# MAIN_CTRL_MMR_MAIN_CTRL_MMR_CFG0_00100000h register map
Vendor: Texas Instruments
Registers are 32-bit, read-write, reset 0x0 unless marked. A register's access mark holds for its fields unless they carry their own. Offsets are as the file gives them; [hi:lo] are bit positions; {n}, {i} and the like mark numbered series.

## main_ctrl_mmr_CFG0 (part 2 of 3)
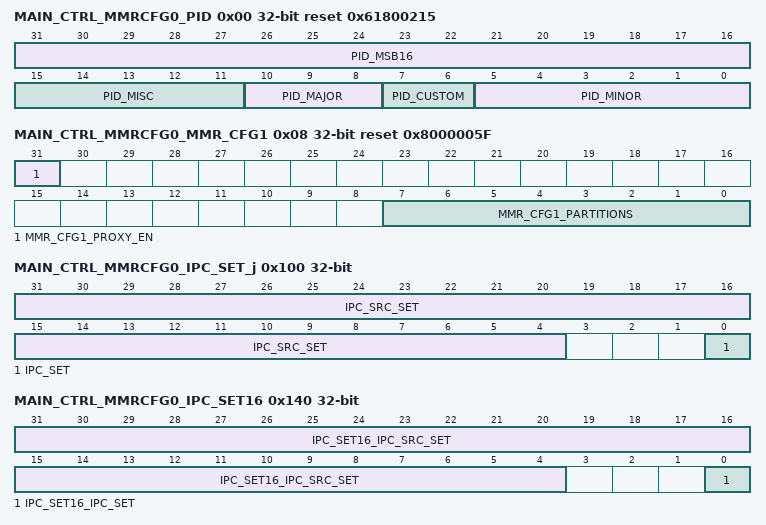
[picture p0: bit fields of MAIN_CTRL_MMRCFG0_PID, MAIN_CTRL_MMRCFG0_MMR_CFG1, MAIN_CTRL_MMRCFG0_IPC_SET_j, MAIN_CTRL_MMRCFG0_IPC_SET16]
0x00 MAIN_CTRL_MMRCFG0_PID ro reset 0x61800215
  [31:16] PID_MSB16 — Reset Source: mod_g_rst_n
  [15:11] PID_MISC — Reset Source: mod_g_rst_n
  [10:8] PID_MAJOR — Reset Source: mod_g_rst_n
  [7:6] PID_CUSTOM — Reset Source: mod_g_rst_n
  [5:0] PID_MINOR — Reset Source: mod_g_rst_n
0x08 MAIN_CTRL_MMRCFG0_MMR_CFG1 ro reset 0x8000005F — Indicates the MMR configuration
  [31] MMR_CFG1_PROXY_EN — Proxy addressing enabled Reset Source: mod_por_rst_n
  [7:0] MMR_CFG1_PARTITIONS — Indicates present partitions Reset Source: mod_por_rst_n
0x100 MAIN_CTRL_MMRCFG0_IPC_SET_j access not given — Generate interprocessor communication interrupt to C71x core0
  [31:4] IPC_SRC_SET — Read returns current valueWrite: 0 - No effect 1 - Sets both corresponding IPC_CLR and the IPC_SET bits Reset Source: mod_g_rst_n (access R/W1TS)
  [0] IPC_SET — Read returns 0Write: 0 - No effect 1 - Sets both corresponding IPC_CLR and the IPC_SET bits Reset Source: mod_g_rst_n (access R/W1TS)
0x140 MAIN_CTRL_MMRCFG0_IPC_SET16 access not given — Generate interprocessor communication interrupt to MAIN R5 cluster0 core0
  [31:4] IPC_SET16_IPC_SRC_SET — Read returns current valueWrite: 0 - No effect 1 - Sets both corresponding IPC_CLR and the IPC_SET bits Reset Source: mod_g_rst_n (access R/W1TS)
  [0] IPC_SET16_IPC_SET — Read returns 0Write: 0 - No effect 1 - Sets both corresponding IPC_CLR and the IPC_SET bits Reset Source: mod_g_rst_n (access R/W1TS)
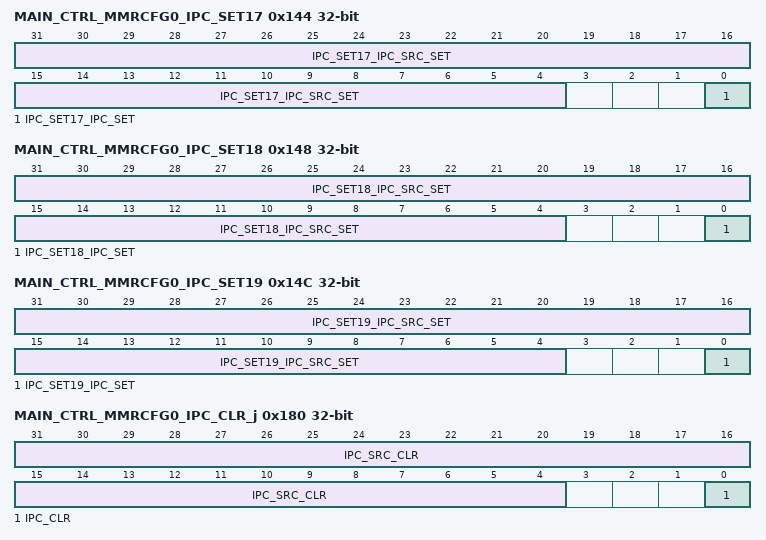
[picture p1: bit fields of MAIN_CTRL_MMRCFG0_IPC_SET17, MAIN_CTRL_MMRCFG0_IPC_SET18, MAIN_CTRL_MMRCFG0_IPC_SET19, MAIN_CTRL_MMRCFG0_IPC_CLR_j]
0x144 MAIN_CTRL_MMRCFG0_IPC_SET17 access not given — Generate interprocessor communication interrupt to MAIN R5 cluster0 core1
  [31:4] IPC_SET17_IPC_SRC_SET — Read returns current valueWrite: 0 - No effect 1 - Sets both corresponding IPC_CLR and the IPC_SET bits Reset Source: mod_g_rst_n (access R/W1TS)
  [0] IPC_SET17_IPC_SET — Read returns 0Write: 0 - No effect 1 - Sets both corresponding IPC_CLR and the IPC_SET bits Reset Source: mod_g_rst_n (access R/W1TS)
0x148 MAIN_CTRL_MMRCFG0_IPC_SET18 access not given — Generate interprocessor communication interrupt to MAIN R5 cluster1 core0
  [31:4] IPC_SET18_IPC_SRC_SET — Read returns current valueWrite: 0 - No effect 1 - Sets both corresponding IPC_CLR and the IPC_SET bits Reset Source: mod_g_rst_n (access R/W1TS)
  [0] IPC_SET18_IPC_SET — Read returns 0Write: 0 - No effect 1 - Sets both corresponding IPC_CLR and the IPC_SET bits Reset Source: mod_g_rst_n (access R/W1TS)
0x14C MAIN_CTRL_MMRCFG0_IPC_SET19 access not given — Generate interprocessor communication interrupt to MAIN R5 cluster1 core1
  [31:4] IPC_SET19_IPC_SRC_SET — Read returns current valueWrite: 0 - No effect 1 - Sets both corresponding IPC_CLR and the IPC_SET bits Reset Source: mod_g_rst_n (access R/W1TS)
  [0] IPC_SET19_IPC_SET — Read returns 0Write: 0 - No effect 1 - Sets both corresponding IPC_CLR and the IPC_SET bits Reset Source: mod_g_rst_n (access R/W1TS)
0x180 MAIN_CTRL_MMRCFG0_IPC_CLR_j access not given — Acknowledge interprocessor communication interrupt to C71x core0
  [31:4] IPC_SRC_CLR — Read returns current valueWrite: 0 - No effect 1 - Clears both corresponding IPC_CLR and the IPC_SET bits Reset Source: mod_g_rst_n (access R/W1TC)
  [0] IPC_CLR — Read returns current valueWrite: 0 - No effect 1 - Clears both corresponding IPC_CLR and the IPC_SET bits Reset Source: mod_g_rst_n (access R/W1TC)
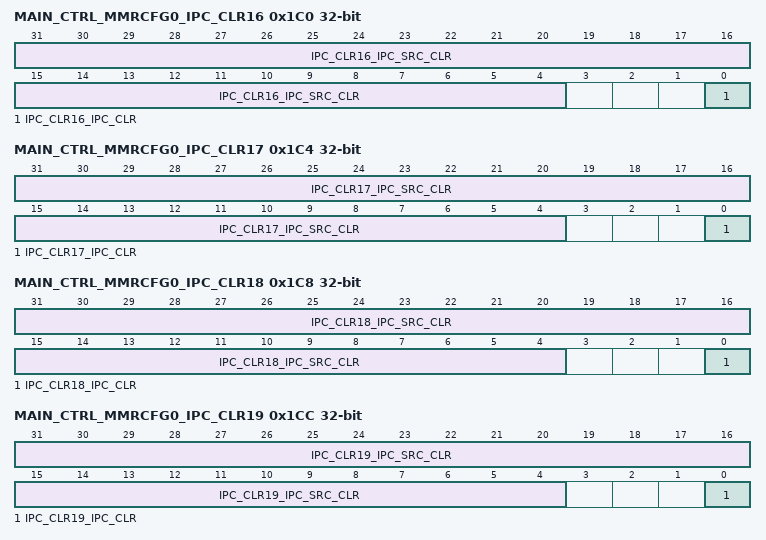
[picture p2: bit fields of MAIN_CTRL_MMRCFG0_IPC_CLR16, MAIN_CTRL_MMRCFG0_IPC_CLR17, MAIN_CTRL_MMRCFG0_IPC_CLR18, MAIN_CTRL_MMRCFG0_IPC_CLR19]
0x1C0 MAIN_CTRL_MMRCFG0_IPC_CLR16 access not given — Acknowledge interprocessor communication interrupt to MAIN R5 cluster0 core0
  [31:4] IPC_CLR16_IPC_SRC_CLR — Read returns current valueWrite: 0 - No effect 1 - Clears both corresponding IPC_CLR and the IPC_SET bits Reset Source: mod_g_rst_n (access R/W1TC)
  [0] IPC_CLR16_IPC_CLR — Read returns current valueWrite: 0 - No effect 1 - Clears both corresponding IPC_CLR and the IPC_SET bits Reset Source: mod_g_rst_n (access R/W1TC)
0x1C4 MAIN_CTRL_MMRCFG0_IPC_CLR17 access not given — Acknowledge interprocessor communication interrupt to MAIN R5 cluster0 core1
  [31:4] IPC_CLR17_IPC_SRC_CLR — Read returns current valueWrite: 0 - No effect 1 - Clears both corresponding IPC_CLR and the IPC_SET bits Reset Source: mod_g_rst_n (access R/W1TC)
  [0] IPC_CLR17_IPC_CLR — Read returns current valueWrite: 0 - No effect 1 - Clears both corresponding IPC_CLR and the IPC_SET bits Reset Source: mod_g_rst_n (access R/W1TC)
0x1C8 MAIN_CTRL_MMRCFG0_IPC_CLR18 access not given — Acknowledge interprocessor communication interrupt to MAIN R5 cluster1 core2
  [31:4] IPC_CLR18_IPC_SRC_CLR — Read returns current valueWrite: 0 - No effect 1 - Clears both corresponding IPC_CLR and the IPC_SET bits Reset Source: mod_g_rst_n (access R/W1TC)
  [0] IPC_CLR18_IPC_CLR — Read returns current valueWrite: 0 - No effect 1 - Clears both corresponding IPC_CLR and the IPC_SET bits Reset Source: mod_g_rst_n (access R/W1TC)
0x1CC MAIN_CTRL_MMRCFG0_IPC_CLR19 access not given — Acknowledge interprocessor communication interrupt to MAIN R5 cluster1 core3
  [31:4] IPC_CLR19_IPC_SRC_CLR — Read returns current valueWrite: 0 - No effect 1 - Clears both corresponding IPC_CLR and the IPC_SET bits Reset Source: mod_g_rst_n (access R/W1TC)
  [0] IPC_CLR19_IPC_CLR — Read returns current valueWrite: 0 - No effect 1 - Clears both corresponding IPC_CLR and the IPC_SET bits Reset Source: mod_g_rst_n (access R/W1TC)
{0x1008+0x4000*i} MAIN_CTRL_MMRCFG0_LOCK{i}_KICK0 (i=0..3)
  [31:0] LOCK{i}_KICK0 — - KICK0 component Reset Source: mod_g_rst_n
{0x100C+0x4000*i} MAIN_CTRL_MMRCFG0_LOCK{i}_KICK1 (i=0..3)
  [31:0] LOCK{i}_KICK1 — - KICK1 component Reset Source: mod_g_rst_n
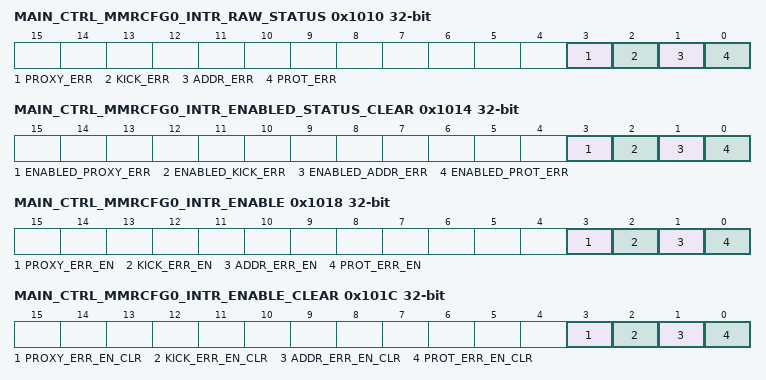
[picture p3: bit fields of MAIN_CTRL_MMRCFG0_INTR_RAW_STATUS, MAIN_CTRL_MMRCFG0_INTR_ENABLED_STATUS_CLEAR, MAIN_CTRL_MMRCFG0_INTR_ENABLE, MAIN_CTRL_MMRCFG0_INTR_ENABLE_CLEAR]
0x1010 MAIN_CTRL_MMRCFG0_INTR_RAW_STATUS access not given
  [3] PROXY_ERR — Proxy0 access violation error. Raw status is read. Write a 1 to set the status. Writing a 0 has no effect. Reset Source: mod_g_rst_n (access R/W1TS)
  [2] KICK_ERR — Kick access violation error. Raw status is read. Write a 1 to set the status. Writing a 0 has no effect. Reset Source: mod_g_rst_n (access R/W1TS)
  [1] ADDR_ERR — Addressing violation error. Raw status is read. Write a 1 to set the status. Writing a 0 has no effect. Reset Source: mod_g_rst_n (access R/W1TS)
  [0] PROT_ERR — Protection violation error. Raw status is read. Write a 1 to set the status. Writing a 0 has no effect. Reset Source: mod_g_rst_n (access R/W1TS)
0x1014 MAIN_CTRL_MMRCFG0_INTR_ENABLED_STATUS_CLEAR access not given
  [3] ENABLED_PROXY_ERR — Proxy0 access violation error. Enabled status is read. Write a 1 to clear the status. Writing a 0 has no effect. Reset Source: mod_g_rst_n (access R/W1TC)
  [2] ENABLED_KICK_ERR — Kick access violation error. Enabled status is read. Write a 1 to clear the status. Writing a 0 has no effect. Reset Source: mod_g_rst_n (access R/W1TC)
  [1] ENABLED_ADDR_ERR — Addressing violation error. Enabled status is read. Write a 1 to clear the status. Writing a 0 has no effect. Reset Source: mod_g_rst_n (access R/W1TC)
  [0] ENABLED_PROT_ERR — Protection violation error. Enabled status is read. Write a 1 to clear the status. Writing a 0 has no effect. Reset Source: mod_g_rst_n (access R/W1TC)
0x1018 MAIN_CTRL_MMRCFG0_INTR_ENABLE access not given
  [3] PROXY_ERR_EN — Proxy0 access violation error enable. Write a 1 to set the enable. Writing a 0 has no effect. Reset Source: mod_g_rst_n (access R/W1TS)
  [2] KICK_ERR_EN — Kick access violation error enable. Write a 1 to set the enable. Writing a 0 has no effect. Reset Source: mod_g_rst_n (access R/W1TS)
  [1] ADDR_ERR_EN — Addressing violation error enable. Write a 1 to set the enable. Writing a 0 has no effect. Reset Source: mod_g_rst_n (access R/W1TS)
  [0] PROT_ERR_EN — Protection violation error enable. Write a 1 to set the enable. Writing a 0 has no effect. Reset Source: mod_g_rst_n (access R/W1TS)
0x101C MAIN_CTRL_MMRCFG0_INTR_ENABLE_CLEAR access not given
  [3] PROXY_ERR_EN_CLR — Proxy0 access violation error enable clear. Write a 1 to clear the enable. Writing a 0 has no effect. Reset Source: mod_g_rst_n (access R/W1TC)
  [2] KICK_ERR_EN_CLR — Kick access violation error enable clear. Write a 1 to clear the enable. Writing a 0 has no effect. Reset Source: mod_g_rst_n (access R/W1TC)
  [1] ADDR_ERR_EN_CLR — Addressing violation error enable clear. Write a 1 to clear the enable. Writing a 0 has no effect. Reset Source: mod_g_rst_n (access R/W1TC)
  [0] PROT_ERR_EN_CLR — Protection violation error enable clear. Write a 1 to clear the enable. Writing a 0 has no effect. Reset Source: mod_g_rst_n (access R/W1TC)
0x1020 MAIN_CTRL_MMRCFG0_EOI
  [7:0] EOI_VECTOR — EOI vector value. Write this with interrupt distribution value in the chip. Reset Source: mod_g_rst_n
0x1024 MAIN_CTRL_MMRCFG0_FAULT_ADDRESS ro
  [31:0] FAULT_ADDR — Fault Address. Reset Source: mod_g_rst_n
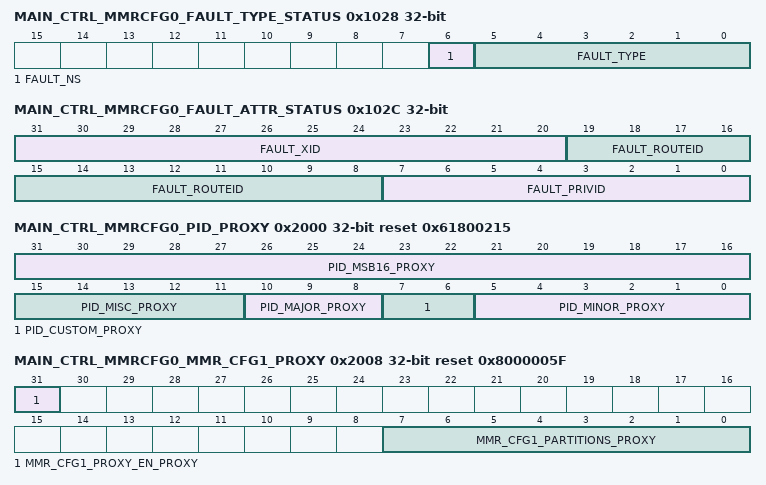
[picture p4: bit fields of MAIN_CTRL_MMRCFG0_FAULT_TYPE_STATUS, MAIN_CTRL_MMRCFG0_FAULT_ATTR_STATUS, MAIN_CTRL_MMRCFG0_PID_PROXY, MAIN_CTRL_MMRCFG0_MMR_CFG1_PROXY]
0x1028 MAIN_CTRL_MMRCFG0_FAULT_TYPE_STATUS ro
  [6] FAULT_NS — Non-secure access. Reset Source: mod_g_rst_n
  [5:0] FAULT_TYPE — Fault Type 10_0000 = Supervisor read fault - priv = 1 dir = 1 dtype != 1 01_0000 = Supervisor write fault - priv = 1 dir = 0 00_1000 = Supervisor execute fault - priv = 1 dir = 1 dtype = 1 00_0100 = User read fault - priv = 0 dir = 1 dtype = 1 00_0010 = User write fault - priv = 0 dir = 0 00_0001 = User execute fault - priv = 0 dir = 1 dtype = 1 00_0000 = No fault Reset Source: mod_g_rst_n
0x102C MAIN_CTRL_MMRCFG0_FAULT_ATTR_STATUS ro
  [31:20] FAULT_XID — XID. Reset Source: mod_g_rst_n
  [19:8] FAULT_ROUTEID — Route ID. Reset Source: mod_g_rst_n
  [7:0] FAULT_PRIVID — Privilege ID. Reset Source: mod_g_rst_n
0x1030 MAIN_CTRL_MMRCFG0_FAULT_CLEAR wo
  [0] FAULT_CLR — Fault clear. Writing a 1 clears the current fault. Writing a 0 has no effect. Reset Source: mod_g_rst_n
{0x1100+0x4000*i} MAIN_CTRL_MMRCFG0_CLAIMREG_P{i}_R0_READONLY ro (i=0..3)
  [31:0] CLAIMREG_P{i}_R0_READONLY — Claim bits for Partition {i} Reset Source: mod_g_rst_n
{0x1108+0x4000*i} MAIN_CTRL_MMRCFG0_CLAIMREG_P{i}_R2_READONLY ro (i=0..2)
  [31:0] CLAIMREG_P{i}_R2_READONLY — Claim bits for Partition {i} Reset Source: mod_g_rst_n
{0x110C+0x4000*i} MAIN_CTRL_MMRCFG0_CLAIMREG_P{i}_R3_READONLY ro (i=0..2)
  [31:0] CLAIMREG_P{i}_R3_READONLY — Claim bits for Partition {i} Reset Source: mod_g_rst_n
{0x1118+0x4000*i} MAIN_CTRL_MMRCFG0_CLAIMREG_P{i}_R6_READONLY ro (i=0..2)
  [31:0] CLAIMREG_P{i}_R6_READONLY — Claim bits for Partition {i} Reset Source: mod_g_rst_n
0x2000 MAIN_CTRL_MMRCFG0_PID_PROXY ro reset 0x61800215
  [31:16] PID_MSB16_PROXY — Reset Source: mod_g_rst_n
  [15:11] PID_MISC_PROXY — Reset Source: mod_g_rst_n
  [10:8] PID_MAJOR_PROXY — Reset Source: mod_g_rst_n
  [7:6] PID_CUSTOM_PROXY — Reset Source: mod_g_rst_n
  [5:0] PID_MINOR_PROXY — Reset Source: mod_g_rst_n
0x2008 MAIN_CTRL_MMRCFG0_MMR_CFG1_PROXY ro reset 0x8000005F — Indicates the MMR configuration
  [31] MMR_CFG1_PROXY_EN_PROXY — Proxy addressing enabled Reset Source: mod_por_rst_n
  [7:0] MMR_CFG1_PARTITIONS_PROXY — Indicates present partitions Reset Source: mod_por_rst_n
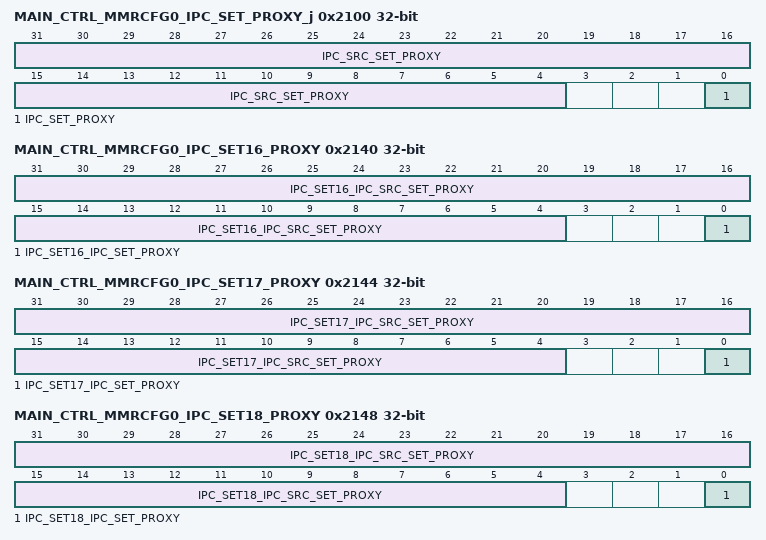
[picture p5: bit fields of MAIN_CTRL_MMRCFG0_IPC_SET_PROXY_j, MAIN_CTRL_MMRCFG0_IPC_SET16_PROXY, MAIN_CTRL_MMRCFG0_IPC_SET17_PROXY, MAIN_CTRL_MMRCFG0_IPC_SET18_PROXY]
0x2100 MAIN_CTRL_MMRCFG0_IPC_SET_PROXY_j access not given — Generate interprocessor communication interrupt to C71x core0
  [31:4] IPC_SRC_SET_PROXY — Read returns current valueWrite: 0 - No effect 1 - Sets both corresponding IPC_CLR and the IPC_SET bits Reset Source: mod_g_rst_n (access R/W1TS)
  [0] IPC_SET_PROXY — Read returns 0Write: 0 - No effect 1 - Sets both corresponding IPC_CLR and the IPC_SET bits Reset Source: mod_g_rst_n (access R/W1TS)
0x2140 MAIN_CTRL_MMRCFG0_IPC_SET16_PROXY access not given — Generate interprocessor communication interrupt to MAIN R5 cluster0 core0
  [31:4] IPC_SET16_IPC_SRC_SET_PROXY — Read returns current valueWrite: 0 - No effect 1 - Sets both corresponding IPC_CLR and the IPC_SET bits Reset Source: mod_g_rst_n (access R/W1TS)
  [0] IPC_SET16_IPC_SET_PROXY — Read returns 0Write: 0 - No effect 1 - Sets both corresponding IPC_CLR and the IPC_SET bits Reset Source: mod_g_rst_n (access R/W1TS)
0x2144 MAIN_CTRL_MMRCFG0_IPC_SET17_PROXY access not given — Generate interprocessor communication interrupt to MAIN R5 cluster0 core1
  [31:4] IPC_SET17_IPC_SRC_SET_PROXY — Read returns current valueWrite: 0 - No effect 1 - Sets both corresponding IPC_CLR and the IPC_SET bits Reset Source: mod_g_rst_n (access R/W1TS)
  [0] IPC_SET17_IPC_SET_PROXY — Read returns 0Write: 0 - No effect 1 - Sets both corresponding IPC_CLR and the IPC_SET bits Reset Source: mod_g_rst_n (access R/W1TS)
0x2148 MAIN_CTRL_MMRCFG0_IPC_SET18_PROXY access not given — Generate interprocessor communication interrupt to MAIN R5 cluster1 core0
  [31:4] IPC_SET18_IPC_SRC_SET_PROXY — Read returns current valueWrite: 0 - No effect 1 - Sets both corresponding IPC_CLR and the IPC_SET bits Reset Source: mod_g_rst_n (access R/W1TS)
  [0] IPC_SET18_IPC_SET_PROXY — Read returns 0Write: 0 - No effect 1 - Sets both corresponding IPC_CLR and the IPC_SET bits Reset Source: mod_g_rst_n (access R/W1TS)
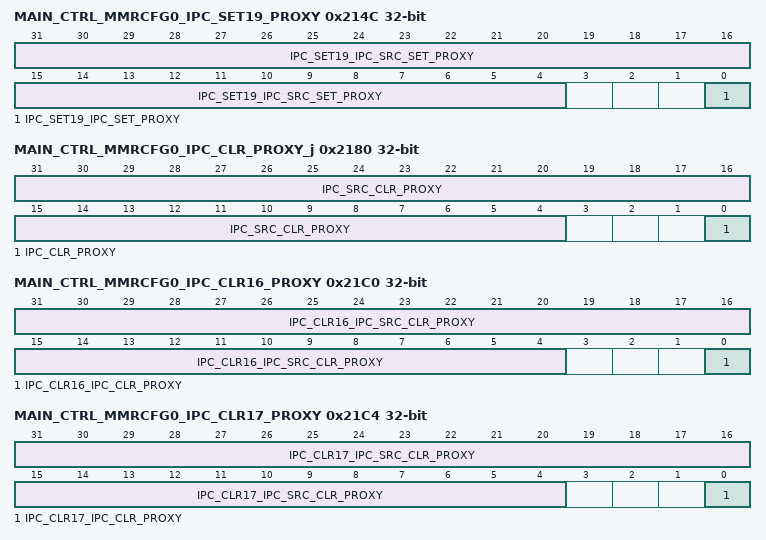
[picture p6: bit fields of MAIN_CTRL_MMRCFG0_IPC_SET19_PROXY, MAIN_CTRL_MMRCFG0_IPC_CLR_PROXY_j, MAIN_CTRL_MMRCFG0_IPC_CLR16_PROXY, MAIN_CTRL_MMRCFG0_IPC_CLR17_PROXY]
0x214C MAIN_CTRL_MMRCFG0_IPC_SET19_PROXY access not given — Generate interprocessor communication interrupt to MAIN R5 cluster1 core1
  [31:4] IPC_SET19_IPC_SRC_SET_PROXY — Read returns current valueWrite: 0 - No effect 1 - Sets both corresponding IPC_CLR and the IPC_SET bits Reset Source: mod_g_rst_n (access R/W1TS)
  [0] IPC_SET19_IPC_SET_PROXY — Read returns 0Write: 0 - No effect 1 - Sets both corresponding IPC_CLR and the IPC_SET bits Reset Source: mod_g_rst_n (access R/W1TS)
0x2180 MAIN_CTRL_MMRCFG0_IPC_CLR_PROXY_j access not given — Acknowledge interprocessor communication interrupt to C71x core0
  [31:4] IPC_SRC_CLR_PROXY — Read returns current valueWrite: 0 - No effect 1 - Clears both corresponding IPC_CLR and the IPC_SET bits Reset Source: mod_g_rst_n (access R/W1TC)
  [0] IPC_CLR_PROXY — Read returns current valueWrite: 0 - No effect 1 - Clears both corresponding IPC_CLR and the IPC_SET bits Reset Source: mod_g_rst_n (access R/W1TC)
0x21C0 MAIN_CTRL_MMRCFG0_IPC_CLR16_PROXY access not given — Acknowledge interprocessor communication interrupt to MAIN R5 cluster0 core0
  [31:4] IPC_CLR16_IPC_SRC_CLR_PROXY — Read returns current valueWrite: 0 - No effect 1 - Clears both corresponding IPC_CLR and the IPC_SET bits Reset Source: mod_g_rst_n (access R/W1TC)
  [0] IPC_CLR16_IPC_CLR_PROXY — Read returns current valueWrite: 0 - No effect 1 - Clears both corresponding IPC_CLR and the IPC_SET bits Reset Source: mod_g_rst_n (access R/W1TC)
0x21C4 MAIN_CTRL_MMRCFG0_IPC_CLR17_PROXY access not given — Acknowledge interprocessor communication interrupt to MAIN R5 cluster0 core1
  [31:4] IPC_CLR17_IPC_SRC_CLR_PROXY — Read returns current valueWrite: 0 - No effect 1 - Clears both corresponding IPC_CLR and the IPC_SET bits Reset Source: mod_g_rst_n (access R/W1TC)
  [0] IPC_CLR17_IPC_CLR_PROXY — Read returns current valueWrite: 0 - No effect 1 - Clears both corresponding IPC_CLR and the IPC_SET bits Reset Source: mod_g_rst_n (access R/W1TC)
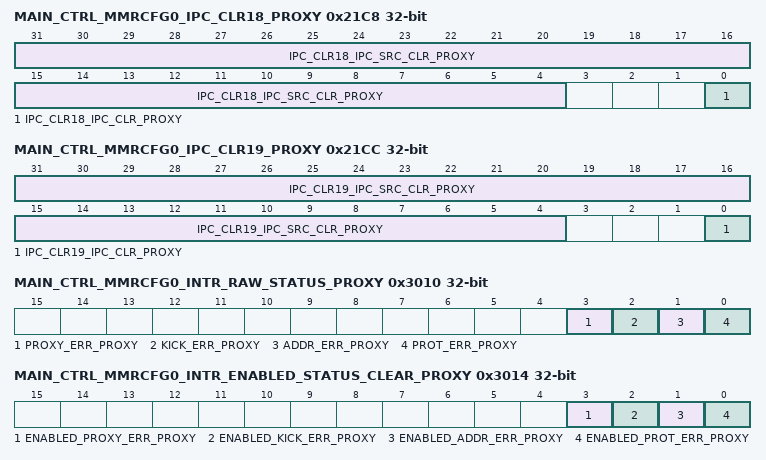
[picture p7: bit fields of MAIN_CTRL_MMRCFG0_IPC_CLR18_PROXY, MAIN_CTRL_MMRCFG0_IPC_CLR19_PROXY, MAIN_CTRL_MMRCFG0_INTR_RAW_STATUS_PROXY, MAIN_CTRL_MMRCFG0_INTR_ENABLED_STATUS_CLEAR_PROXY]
0x21C8 MAIN_CTRL_MMRCFG0_IPC_CLR18_PROXY access not given — Acknowledge interprocessor communication interrupt to MAIN R5 cluster1 core2
  [31:4] IPC_CLR18_IPC_SRC_CLR_PROXY — Read returns current valueWrite: 0 - No effect 1 - Clears both corresponding IPC_CLR and the IPC_SET bits Reset Source: mod_g_rst_n (access R/W1TC)
  [0] IPC_CLR18_IPC_CLR_PROXY — Read returns current valueWrite: 0 - No effect 1 - Clears both corresponding IPC_CLR and the IPC_SET bits Reset Source: mod_g_rst_n (access R/W1TC)
0x21CC MAIN_CTRL_MMRCFG0_IPC_CLR19_PROXY access not given — Acknowledge interprocessor communication interrupt to MAIN R5 cluster1 core3
  [31:4] IPC_CLR19_IPC_SRC_CLR_PROXY — Read returns current valueWrite: 0 - No effect 1 - Clears both corresponding IPC_CLR and the IPC_SET bits Reset Source: mod_g_rst_n (access R/W1TC)
  [0] IPC_CLR19_IPC_CLR_PROXY — Read returns current valueWrite: 0 - No effect 1 - Clears both corresponding IPC_CLR and the IPC_SET bits Reset Source: mod_g_rst_n (access R/W1TC)
{0x3008+0x4000*i} MAIN_CTRL_MMRCFG0_LOCK{i}_KICK0_PROXY (i=0..3)
  [31:0] LOCK{i}_KICK0_PROXY — - KICK0 component Reset Source: mod_g_rst_n
{0x300C+0x4000*i} MAIN_CTRL_MMRCFG0_LOCK{i}_KICK1_PROXY (i=0..3)
  [31:0] LOCK{i}_KICK1_PROXY — - KICK1 component Reset Source: mod_g_rst_n
0x3010 MAIN_CTRL_MMRCFG0_INTR_RAW_STATUS_PROXY access not given
  [3] PROXY_ERR_PROXY — Proxy0 access violation error. Raw status is read. Write a 1 to set the status. Writing a 0 has no effect. Reset Source: mod_g_rst_n (access R/W1TS)
  [2] KICK_ERR_PROXY — Kick access violation error. Raw status is read. Write a 1 to set the status. Writing a 0 has no effect. Reset Source: mod_g_rst_n (access R/W1TS)
  [1] ADDR_ERR_PROXY — Addressing violation error. Raw status is read. Write a 1 to set the status. Writing a 0 has no effect. Reset Source: mod_g_rst_n (access R/W1TS)
  [0] PROT_ERR_PROXY — Protection violation error. Raw status is read. Write a 1 to set the status. Writing a 0 has no effect. Reset Source: mod_g_rst_n (access R/W1TS)
0x3014 MAIN_CTRL_MMRCFG0_INTR_ENABLED_STATUS_CLEAR_PROXY access not given
  [3] ENABLED_PROXY_ERR_PROXY — Proxy0 access violation error. Enabled status is read. Write a 1 to clear the status. Writing a 0 has no effect. Reset Source: mod_g_rst_n (access R/W1TC)
  [2] ENABLED_KICK_ERR_PROXY — Kick access violation error. Enabled status is read. Write a 1 to clear the status. Writing a 0 has no effect. Reset Source: mod_g_rst_n (access R/W1TC)
  [1] ENABLED_ADDR_ERR_PROXY — Addressing violation error. Enabled status is read. Write a 1 to clear the status. Writing a 0 has no effect. Reset Source: mod_g_rst_n (access R/W1TC)
  [0] ENABLED_PROT_ERR_PROXY — Protection violation error. Enabled status is read. Write a 1 to clear the status. Writing a 0 has no effect. Reset Source: mod_g_rst_n (access R/W1TC)
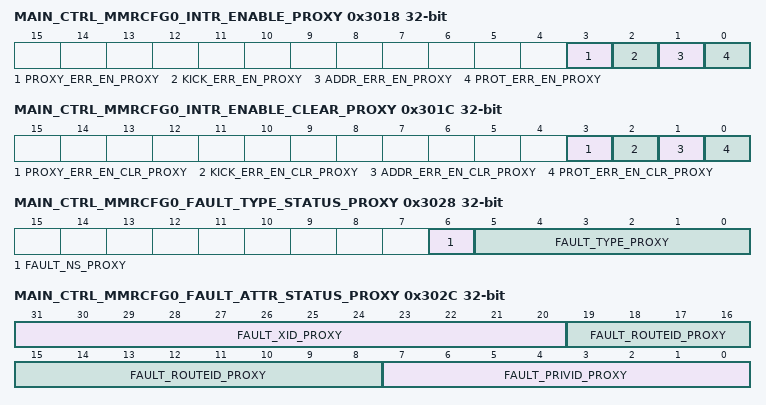
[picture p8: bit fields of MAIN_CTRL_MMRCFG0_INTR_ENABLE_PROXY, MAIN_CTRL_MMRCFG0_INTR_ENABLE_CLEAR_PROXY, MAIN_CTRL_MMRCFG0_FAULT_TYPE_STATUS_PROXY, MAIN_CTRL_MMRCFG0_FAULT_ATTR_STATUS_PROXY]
0x3018 MAIN_CTRL_MMRCFG0_INTR_ENABLE_PROXY access not given
  [3] PROXY_ERR_EN_PROXY — Proxy0 access violation error enable. Write a 1 to set the enable. Writing a 0 has no effect. Reset Source: mod_g_rst_n (access R/W1TS)
  [2] KICK_ERR_EN_PROXY — Kick access violation error enable. Write a 1 to set the enable. Writing a 0 has no effect. Reset Source: mod_g_rst_n (access R/W1TS)
  [1] ADDR_ERR_EN_PROXY — Addressing violation error enable. Write a 1 to set the enable. Writing a 0 has no effect. Reset Source: mod_g_rst_n (access R/W1TS)
  [0] PROT_ERR_EN_PROXY — Protection violation error enable. Write a 1 to set the enable. Writing a 0 has no effect. Reset Source: mod_g_rst_n (access R/W1TS)
0x301C MAIN_CTRL_MMRCFG0_INTR_ENABLE_CLEAR_PROXY access not given
  [3] PROXY_ERR_EN_CLR_PROXY — Proxy0 access violation error enable clear. Write a 1 to clear the enable. Writing a 0 has no effect. Reset Source: mod_g_rst_n (access R/W1TC)
  [2] KICK_ERR_EN_CLR_PROXY — Kick access violation error enable clear. Write a 1 to clear the enable. Writing a 0 has no effect. Reset Source: mod_g_rst_n (access R/W1TC)
  [1] ADDR_ERR_EN_CLR_PROXY — Addressing violation error enable clear. Write a 1 to clear the enable. Writing a 0 has no effect. Reset Source: mod_g_rst_n (access R/W1TC)
  [0] PROT_ERR_EN_CLR_PROXY — Protection violation error enable clear. Write a 1 to clear the enable. Writing a 0 has no effect. Reset Source: mod_g_rst_n (access R/W1TC)
0x3020 MAIN_CTRL_MMRCFG0_EOI_PROXY
  [7:0] EOI_VECTOR_PROXY — EOI vector value. Write this with interrupt distribution value in the chip. Reset Source: mod_g_rst_n
0x3024 MAIN_CTRL_MMRCFG0_FAULT_ADDRESS_PROXY ro
  [31:0] FAULT_ADDR_PROXY — Fault Address. Reset Source: mod_g_rst_n
0x3028 MAIN_CTRL_MMRCFG0_FAULT_TYPE_STATUS_PROXY ro
  [6] FAULT_NS_PROXY — Non-secure access. Reset Source: mod_g_rst_n
  [5:0] FAULT_TYPE_PROXY — Fault Type 10_0000 = Supervisor read fault - priv = 1 dir = 1 dtype != 1 01_0000 = Supervisor write fault - priv = 1 dir = 0 00_1000 = Supervisor execute fault - priv = 1 dir = 1 dtype = 1 00_0100 = User read fault - priv = 0 dir = 1 dtype = 1 00_0010 = User write fault - priv = 0 dir = 0 00_0001 = User execute fault - priv = 0 dir = 1 dtype = 1 00_0000 = No fault Reset Source: mod_g_rst_n
0x302C MAIN_CTRL_MMRCFG0_FAULT_ATTR_STATUS_PROXY ro
  [31:20] FAULT_XID_PROXY — XID. Reset Source: mod_g_rst_n
  [19:8] FAULT_ROUTEID_PROXY — Route ID. Reset Source: mod_g_rst_n
  [7:0] FAULT_PRIVID_PROXY — Privilege ID. Reset Source: mod_g_rst_n
0x3030 MAIN_CTRL_MMRCFG0_FAULT_CLEAR_PROXY wo
  [0] FAULT_CLR_PROXY — Fault clear. Writing a 1 clears the current fault. Writing a 0 has no effect. Reset Source: mod_g_rst_n
{0x3100+4i} MAIN_CTRL_MMRCFG0_CLAIMREG_P0_R{i} (i=0..6)
  [31:0] CLAIMREG_P0_R{i} — Claim bits for Partition 0 Reset Source: mod_g_rst_n
0x4044 MAIN_CTRL_MMRCFG0_ENET1_CTRL reset 0x2 — Controls Ethernet Port1 operation
  [2:0] ENET1_CTRL_PORT_MODE_SEL — Selects Ethernet switch Port1 interface Field values (others are reserved):3'b000 - GMII/MII (not supported)3'b001 - RMII3'b010 - RGMII3'b011 - SGMII3'b100 - QSGMII (not supported)3'b101 - XFI (not supported)3'b110 - QSGMII_SUB (not supported)3'b111 - Reserved Reset Source: sys_por_rst_n
0x4048 MAIN_CTRL_MMRCFG0_ENET2_CTRL reset 0x2 — Controls Ethernet Port2 operation
  [2:0] ENET2_CTRL_PORT_MODE_SEL — Selects Ethernet switch Port2 interface Field values (others are reserved):3'b000 - GMII/MII (not supported)3'b001 - RMII3'b010 - RGMII3'b011 - SGMII3'b100 - QSGMII (not supported)3'b101 - XFI (not supported)3'b110 - QSGMII_SUB (not supported)3'b111 - Reserved Reset Source: sys_por_rst_n
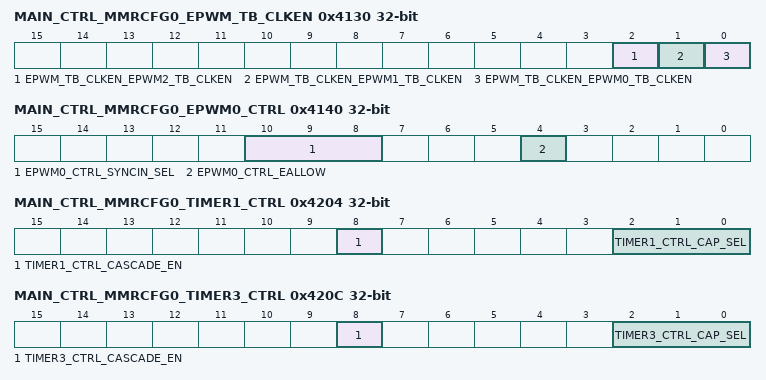
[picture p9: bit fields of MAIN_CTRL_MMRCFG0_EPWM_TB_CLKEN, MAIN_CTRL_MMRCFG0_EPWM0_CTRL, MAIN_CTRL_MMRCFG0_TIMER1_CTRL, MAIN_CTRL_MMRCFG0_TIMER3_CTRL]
0x4130 MAIN_CTRL_MMRCFG0_EPWM_TB_CLKEN — Controls Timebase Counter of EPWM Modules
  [2] EPWM_TB_CLKEN_EPWM2_TB_CLKEN — Enabled Timebase Clock of EPWM2 When SetField values (others are reserved):1'b0 - Disable1'b1 - Enable Reset Source: mod_g_rst_n
  [1] EPWM_TB_CLKEN_EPWM1_TB_CLKEN — EnablesTimebase Clock of EPWM1 When SetField values (others are reserved):1'b0 - Disable1'b1 - Enable Reset Source: mod_g_rst_n
  [0] EPWM_TB_CLKEN_EPWM0_TB_CLKEN — EnablesTimebase Clock of EPWM0 When SetField values (others are reserved):1'b0 - Disable1'b1 - Enable Reset Source: mod_g_rst_n
0x4140 MAIN_CTRL_MMRCFG0_EPWM0_CTRL — Controls EPWM0 Operation
  [10:8] EPWM0_CTRL_SYNCIN_SEL — Selects the source of the EPWM0 synchronization inputField values (others are reserved):3'b000 - EPWM0_SYNCIN (Pin)undefined - undefined3'b010 - TimeSync Intr Router outl.203'b011 - CPSW CPTS Compare Event Reset Source: mod_g_rst_n
  [4] EPWM0_CTRL_EALLOW — Enable write access to EPWM tripzone registersField values (others are reserved):1'b0 - Disable1'b1 - Enable Reset Source: mod_g_rst_n
0x4144 MAIN_CTRL_MMRCFG0_EPWM1_CTRL — Controls EPWM1 Operation
  [4] EPWM1_CTRL_EALLOW — Enable write access to EPWM tripzone registersField values (others are reserved):1'b0 - Disable1'b1 - Enable Reset Source: mod_g_rst_n
0x4148 MAIN_CTRL_MMRCFG0_EPWM2_CTRL — Controls EPWM2 Operation
  [4] EPWM2_CTRL_EALLOW — Enable write access to EPWM tripzone registersField values (others are reserved):1'b0 - Disable1'b1 - Enable Reset Source: mod_g_rst_n
0x4200 MAIN_CTRL_MMRCFG0_TIMER0_CTRL — Controls TIMER0 operation
  [2:0] TIMER0_CTRL_CAP_SEL — Selects the TIMERIO input pin for capture input signal. This control is only used when TIMER0 is configured for capture operation.Field values (others are reserved):3'b000 - Use TIMERIO0 pin3'b001 - Use TIMERIO1 pin3'b010 - Use TIMERIO2 pin3'b011 - Use TIMERIO3 pin3'b100 - Use TIMERIO4 pin3'b101 - Use TIMERIO5 pin3'b110 - Use TIMERIO6 pin3'b111 - Use TIMERIO7 pin Reset Source: sys_por_rst_n
0x4204 MAIN_CTRL_MMRCFG0_TIMER1_CTRL — Controls TIMER1 operation
  [8] TIMER1_CTRL_CASCADE_EN — Enables cascading of TIMER1 to TIMER0Field values (others are reserved):1'b0 - Cascading disabled1'b1 - Cascading enabled Reset Source: sys_por_rst_n
  [2:0] TIMER1_CTRL_CAP_SEL — Selects the TIMERIO input pin for capture input signal. This control is only used when TIMER1 is configured for capture operation.Field values (others are reserved):3'b000 - Use TIMERIO0 pin3'b001 - Use TIMERIO1 pin3'b010 - Use TIMERIO2 pin3'b011 - Use TIMERIO3 pin3'b100 - Use TIMERIO4 pin3'b101 - Use TIMERIO5 pin3'b110 - Use TIMERIO6 pin3'b111 - Use TIMERIO7 pin Reset Source: sys_por_rst_n
0x4208 MAIN_CTRL_MMRCFG0_TIMER2_CTRL — Controls TIMER2 operation
  [2:0] TIMER2_CTRL_CAP_SEL — Selects the TIMERIO input pin for capture input signal. This control is only used when TIMER2 is configured for capture operation.Field values (others are reserved):3'b000 - Use TIMERIO0 pin3'b001 - Use TIMERIO1 pin3'b010 - Use TIMERIO2 pin3'b011 - Use TIMERIO3 pin3'b100 - Use TIMERIO4 pin3'b101 - Use TIMERIO5 pin3'b110 - Use TIMERIO6 pin3'b111 - Use TIMERIO7 pin Reset Source: sys_por_rst_n
0x420C MAIN_CTRL_MMRCFG0_TIMER3_CTRL — Controls TIMER3 operation
  [8] TIMER3_CTRL_CASCADE_EN — Enables cascading of TIMER3 to TIMER2Field values (others are reserved):1'b0 - Cascading disabled1'b1 - Cascading enabled Reset Source: sys_por_rst_n
  [2:0] TIMER3_CTRL_CAP_SEL — Selects the TIMERIO input pin for capture input signal. This control is only used when TIMER3 is configured for capture operation.Field values (others are reserved):3'b000 - Use TIMERIO0 pin3'b001 - Use TIMERIO1 pin3'b010 - Use TIMERIO2 pin3'b011 - Use TIMERIO3 pin3'b100 - Use TIMERIO4 pin3'b101 - Use TIMERIO5 pin3'b110 - Use TIMERIO6 pin3'b111 - Use TIMERIO7 pin Reset Source: sys_por_rst_n
0x4210 MAIN_CTRL_MMRCFG0_TIMER4_CTRL — Controls TIMER4 operation
  [2:0] TIMER4_CTRL_CAP_SEL — Selects the TIMERIO input pin for capture input signal. This control is only used when TIMER4 is configured for capture operation.Field values (others are reserved):3'b000 - Use TIMERIO0 pin3'b001 - Use TIMERIO1 pin3'b010 - Use TIMERIO2 pin3'b011 - Use TIMERIO3 pin3'b100 - Use TIMERIO4 pin3'b101 - Use TIMERIO5 pin3'b110 - Use TIMERIO6 pin3'b111 - Use TIMERIO7 pin Reset Source: sys_por_rst_n
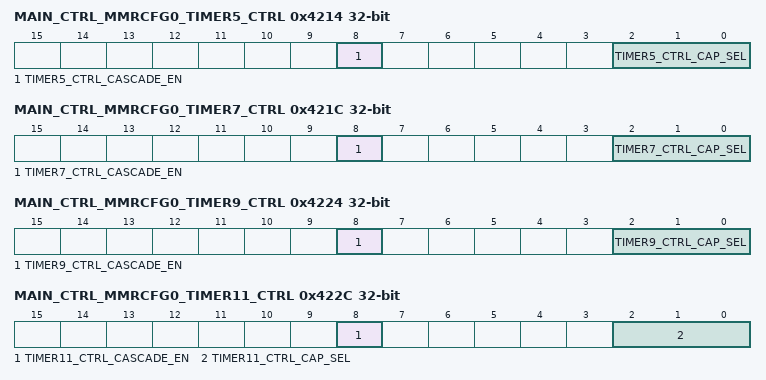
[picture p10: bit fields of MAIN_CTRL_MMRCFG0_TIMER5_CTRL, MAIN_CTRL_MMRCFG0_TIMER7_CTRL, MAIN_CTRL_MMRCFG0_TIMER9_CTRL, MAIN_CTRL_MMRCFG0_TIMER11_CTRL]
0x4214 MAIN_CTRL_MMRCFG0_TIMER5_CTRL — Controls TIMER5 operation
  [8] TIMER5_CTRL_CASCADE_EN — Enables cascading of TIMER5 to TIMER4Field values (others are reserved):1'b0 - Cascading disabled1'b1 - Cascading enabled Reset Source: sys_por_rst_n
  [2:0] TIMER5_CTRL_CAP_SEL — Selects the TIMERIO input pin for capture input signal. This control is only used when TIMER5 is configured for capture operation.Field values (others are reserved):3'b000 - Use TIMERIO0 pin3'b001 - Use TIMERIO1 pin3'b010 - Use TIMERIO2 pin3'b011 - Use TIMERIO3 pin3'b100 - Use TIMERIO4 pin3'b101 - Use TIMERIO5 pin3'b110 - Use TIMERIO6 pin3'b111 - Use TIMERIO7 pin Reset Source: sys_por_rst_n
0x4218 MAIN_CTRL_MMRCFG0_TIMER6_CTRL — Controls TIMER6 operation
  [2:0] TIMER6_CTRL_CAP_SEL — Selects the TIMERIO input pin for capture input signal. This control is only used when TIMER6 is configured for capture operation.Field values (others are reserved):3'b000 - Use TIMERIO0 pin3'b001 - Use TIMERIO1 pin3'b010 - Use TIMERIO2 pin3'b011 - Use TIMERIO3 pin3'b100 - Use TIMERIO4 pin3'b101 - Use TIMERIO5 pin3'b110 - Use TIMERIO6 pin3'b111 - Use TIMERIO7 pin Reset Source: sys_por_rst_n
0x421C MAIN_CTRL_MMRCFG0_TIMER7_CTRL — Controls TIMER7 operation
  [8] TIMER7_CTRL_CASCADE_EN — Enables cascading of TIMER7 to TIMER6Field values (others are reserved):1'b0 - Cascading disabled1'b1 - Cascading enabled Reset Source: sys_por_rst_n
  [2:0] TIMER7_CTRL_CAP_SEL — Selects the TIMERIO input pin for capture input signal. This control is only used when TIMER7 is configured for capture operation.Field values (others are reserved):3'b000 - Use TIMERIO0 pin3'b001 - Use TIMERIO1 pin3'b010 - Use TIMERIO2 pin3'b011 - Use TIMERIO3 pin3'b100 - Use TIMERIO4 pin3'b101 - Use TIMERIO5 pin3'b110 - Use TIMERIO6 pin3'b111 - Use TIMERIO7 pin Reset Source: sys_por_rst_n
0x4220 MAIN_CTRL_MMRCFG0_TIMER8_CTRL — Controls TIMER8 operation
  [2:0] TIMER8_CTRL_CAP_SEL — Selects the TIMERIO input pin for capture input signal. This control is only used when TIMER8 is configured for capture operation.Field values (others are reserved):3'b000 - Use TIMERIO0 pin3'b001 - Use TIMERIO1 pin3'b010 - Use TIMERIO2 pin3'b011 - Use TIMERIO3 pin3'b100 - Use TIMERIO4 pin3'b101 - Use TIMERIO5 pin3'b110 - Use TIMERIO6 pin3'b111 - Use TIMERIO7 pin Reset Source: sys_por_rst_n
0x4224 MAIN_CTRL_MMRCFG0_TIMER9_CTRL — Controls TIMER9 operation
  [8] TIMER9_CTRL_CASCADE_EN — Enables cascading of TIMER9 to TIMER8Field values (others are reserved):1'b0 - Cascading disabled1'b1 - Cascading enabled Reset Source: sys_por_rst_n
  [2:0] TIMER9_CTRL_CAP_SEL — Selects the TIMERIO input pin for capture input signal. This control is only used when TIMER9 is configured for capture operation.Field values (others are reserved):3'b000 - Use TIMERIO0 pin3'b001 - Use TIMERIO1 pin3'b010 - Use TIMERIO2 pin3'b011 - Use TIMERIO3 pin3'b100 - Use TIMERIO4 pin3'b101 - Use TIMERIO5 pin3'b110 - Use TIMERIO6 pin3'b111 - Use TIMERIO7 pin Reset Source: sys_por_rst_n
0x4228 MAIN_CTRL_MMRCFG0_TIMER10_CTRL — Controls TIMER10 operation
  [2:0] TIMER10_CTRL_CAP_SEL — Selects the TIMERIO input pin for capture input signal. This control is only used when TIMER10 is configured for capture operation.Field values (others are reserved):3'b000 - Use TIMERIO0 pin3'b001 - Use TIMERIO1 pin3'b010 - Use TIMERIO2 pin3'b011 - Use TIMERIO3 pin3'b100 - Use TIMERIO4 pin3'b101 - Use TIMERIO5 pin3'b110 - Use TIMERIO6 pin3'b111 - Use TIMERIO7 pin Reset Source: sys_por_rst_n
0x422C MAIN_CTRL_MMRCFG0_TIMER11_CTRL — Controls TIMER11 operation
  [8] TIMER11_CTRL_CASCADE_EN — Enables cascading of TIMER11 to TIMER10Field values (others are reserved):1'b0 - Cascading disabled1'b1 - Cascading enabled Reset Source: sys_por_rst_n
  [2:0] TIMER11_CTRL_CAP_SEL — Selects the TIMERIO input pin for capture input signal. This control is only used when TIMER11 is configured for capture operation.Field values (others are reserved):3'b000 - Use TIMERIO0 pin3'b001 - Use TIMERIO1 pin3'b010 - Use TIMERIO2 pin3'b011 - Use TIMERIO3 pin3'b100 - Use TIMERIO4 pin3'b101 - Use TIMERIO5 pin3'b110 - Use TIMERIO6 pin3'b111 - Use TIMERIO7 pin Reset Source: sys_por_rst_n
0x4230 MAIN_CTRL_MMRCFG0_TIMER12_CTRL — Controls TIMER12 operation
  [2:0] TIMER12_CTRL_CAP_SEL — Selects the TIMERIO input pin for capture input signal. This control is only used when TIMER12 is configured for capture operation.Field values (others are reserved):3'b000 - Use TIMERIO0 pin3'b001 - Use TIMERIO1 pin3'b010 - Use TIMERIO2 pin3'b011 - Use TIMERIO3 pin3'b100 - Use TIMERIO4 pin3'b101 - Use TIMERIO5 pin3'b110 - Use TIMERIO6 pin3'b111 - Use TIMERIO7 pin Reset Source: sys_por_rst_n
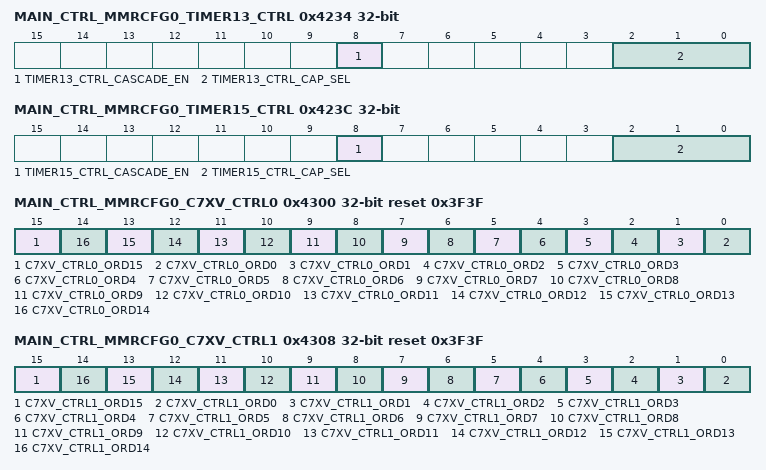
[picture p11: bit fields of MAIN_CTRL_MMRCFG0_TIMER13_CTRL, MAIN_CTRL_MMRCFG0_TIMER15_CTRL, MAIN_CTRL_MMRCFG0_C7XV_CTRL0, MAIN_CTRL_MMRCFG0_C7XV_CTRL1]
0x4234 MAIN_CTRL_MMRCFG0_TIMER13_CTRL — Controls TIMER13 operation
  [8] TIMER13_CTRL_CASCADE_EN — Enables cascading of TIMER13 to TIMER12Field values (others are reserved):1'b0 - Cascading disabled1'b1 - Cascading enabled Reset Source: sys_por_rst_n
  [2:0] TIMER13_CTRL_CAP_SEL — Selects the TIMERIO input pin for capture input signal. This control is only used when TIMER13 is configured for capture operation.Field values (others are reserved):3'b000 - Use TIMERIO0 pin3'b001 - Use TIMERIO1 pin3'b010 - Use TIMERIO2 pin3'b011 - Use TIMERIO3 pin3'b100 - Use TIMERIO4 pin3'b101 - Use TIMERIO5 pin3'b110 - Use TIMERIO6 pin3'b111 - Use TIMERIO7 pin Reset Source: sys_por_rst_n
0x4238 MAIN_CTRL_MMRCFG0_TIMER14_CTRL — Controls TIMER14 operation
  [2:0] TIMER14_CTRL_CAP_SEL — Selects the TIMERIO input pin for capture input signal. This control is only used when TIMER14 is configured for capture operation.Field values (others are reserved):3'b000 - Use TIMERIO0 pin3'b001 - Use TIMERIO1 pin3'b010 - Use TIMERIO2 pin3'b011 - Use TIMERIO3 pin3'b100 - Use TIMERIO4 pin3'b101 - Use TIMERIO5 pin3'b110 - Use TIMERIO6 pin3'b111 - Use TIMERIO7 pin Reset Source: sys_por_rst_n
0x423C MAIN_CTRL_MMRCFG0_TIMER15_CTRL — Controls TIMER15 operation
  [8] TIMER15_CTRL_CASCADE_EN — Enables cascading of TIMER15 to TIMER14Field values (others are reserved):1'b0 - Cascading disabled1'b1 - Cascading enabled Reset Source: sys_por_rst_n
  [2:0] TIMER15_CTRL_CAP_SEL — Selects the TIMERIO input pin for capture input signal. This control is only used when TIMER15 is configured for capture operation.Field values (others are reserved):3'b000 - Use TIMERIO0 pin3'b001 - Use TIMERIO1 pin3'b010 - Use TIMERIO2 pin3'b011 - Use TIMERIO3 pin3'b100 - Use TIMERIO4 pin3'b101 - Use TIMERIO5 pin3'b110 - Use TIMERIO6 pin3'b111 - Use TIMERIO7 pin Reset Source: sys_por_rst_n
{0x4280+4i} MAIN_CTRL_MMRCFG0_TIMERIO{i}_CTRL (i=0..7) — Controls Timer IO muxing
  [3:0] TIMERIO{i}_CTRL_OUT_SEL — Selects the source of the TIMERIO{i} outputField values (others are reserved):4'b0000 - TIMERIO{i} is driven by TIMER0 output4'b0001 - TIMERIO{i} is driven by TIMER1 output4'b0010 - TIMERIO{i} is driven by TIMER2 output4'b0011 - TIMERIO{i} is driven by TIMER3 output4'b0100 - TIMERIO{i} is driven by TIMER4 output4'b0101 - TIMERIO{i} is driven by TIMER5 output4'b0110 - TIMERIO{i} is driven by TIMER6 output4'b0111 - TIMERIO{i} is driven by TIMER7 output4'b1000 - TIMERIO{i} is driven by TIMER8 output4'b1001 - TIMERIO{i} is driven by TIMER9 output4'b1010 - TIMERIO{i} is driven by TIMER10 output4'b1011 - TIMERIO{i} is driven by TIMER11 output4'b1100 - TIMERIO{i} is driven by TIMER12 output4'b1101 - TIMERIO{i} is driven by TIMER13 output4'b1110 - TIMERIO{i} is driven by TIMER14 output4'b1111 - TIMERIO{i} is driven by TIMER15 output Reset Source: sys_por_rst_n
0x4300 MAIN_CTRL_MMRCFG0_C7XV_CTRL0 reset 0x3F3F — Controls Relaxed Ordering by OrderID for the C7xv0 L2 Memory from external accesses. Ordering of accesses to the same 4KB L2 Block is relaxed either between Reads (more strict) or Between both Reads and Writes (more relaxed)
  [15] C7XV_CTRL0_ORD15 — Ordering Rule for Order ID 15 Field values (others are reserved):1'b0 - RELAXED_READ1'b1 - RELAXED_R_TO_W Reset Source: mod_por_rst_n
  [n] C7XV_CTRL0_ORD{n} (n=0..14) — Ordering Rule for Order ID {n}Field values (others are reserved):1'b0 - RELAXED_READ1'b1 - RELAXED_R_TO_W Reset Source: mod_por_rst_n
0x4308 MAIN_CTRL_MMRCFG0_C7XV_CTRL1 reset 0x3F3F — Controls Relaxed Ordering by OrderID for the C7xv1 L2 Memory from external accesses. Ordering of accesses to the same 4KB L2 Block is relaxed either between Reads (more strict) or Between both Reads and Writes (more relaxed)
  [15] C7XV_CTRL1_ORD15 — Ordering Rule for Order ID 15 Field values (others are reserved):1'b0 - RELAXED_READ1'b1 - RELAXED_R_TO_W Reset Source: mod_por_rst_n
  [n] C7XV_CTRL1_ORD{n} (n=0..14) — Ordering Rule for Order ID {n}Field values (others are reserved):1'b0 - RELAXED_READ1'b1 - RELAXED_R_TO_W Reset Source: mod_por_rst_n
0x44C0 MAIN_CTRL_MMRCFG0_EMMC0_STAT ro — For determining state of MMCSD 1.8V Signalling
  [0] EMMC0_STAT_SIG1P8_EN — Status of 1.8V Signal Activate from EMMC0 ModuleField values (others are reserved):1'b0 - DISABLE_1P8V_SIGNALLING1'b1 - ENABLE_1P8V_SIGNALLING Reset Source: mod_g_rst_n
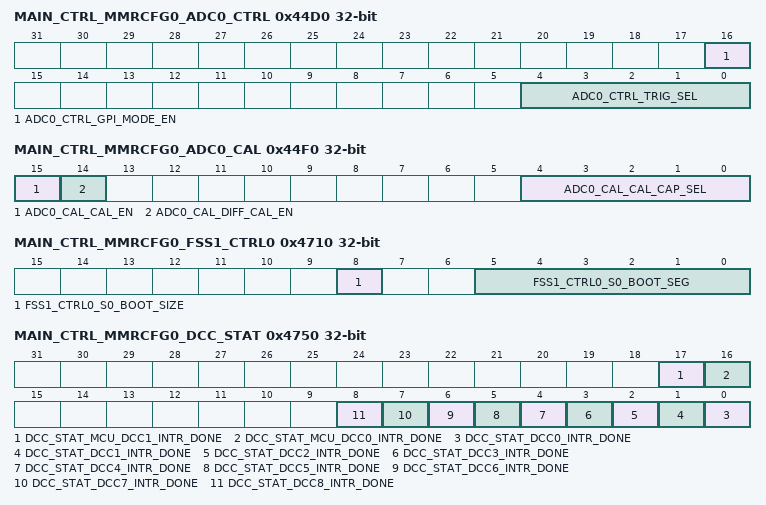
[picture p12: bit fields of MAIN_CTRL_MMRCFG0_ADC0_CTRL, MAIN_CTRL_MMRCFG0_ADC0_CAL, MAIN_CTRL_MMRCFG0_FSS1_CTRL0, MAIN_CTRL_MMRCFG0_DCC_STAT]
0x44D0 MAIN_CTRL_MMRCFG0_ADC0_CTRL — Controls operation of ADC0
  [16] ADC0_CTRL_GPI_MODE_EN — Enables ADC0 data pins to be used as general purpose inputs when set. This signal is tied to the en_dig_test input of MCU_ADC0 Reset Source: mod_g_rst_n
  [4:0] ADC0_CTRL_TRIG_SEL — Selects the source of the ADC hardware event triggerField values (others are reserved):5'b00000 - ADC_EXT_TRIGGER0 (Pin)5'b00001 - 0 - Reserved5'b00010 - EPWM SOCA_OUT5'b00011 - EPWM SOCB_OUT5'b00100 - 0 - Reserved5'b00101 - 0 - Reserved5'b00110 - 0 - Reserved5'b00111 - 0 - Reserved5'b01000 - 0 - Reserved5'b01001 - 0 - Reserved5'b01010 - 0 - Reserved5'b01011 - 0 - Reserved5'b01100 - 0 - Reserved5'b01101 - 0 - Reserved5'b01110 - WKUP_TIMER0 PWM5'b01111 - WKUP_TIMER1 PWM5'b10000 - TIMER0 PWM 5'b10001 - TIMER1 PWM 5'b10010 - TIMER2 PWM 5'b10011 - TIMER3 PWM 5'b10100 - TIMER4 PWM 5'b10101 - TIMER5 PWM 5'b10110 - TIMER6 PWM 5'b10111 - TIMER7 PWM 5'b11000 - TIMER8 PWM 5'b11001 - TIMER9 PWM 5'b11010 - TIMER10 PWM 5'b11011 - TIMER11 PWM 5'b11100 - TIMER12 PWM5'b11101 - TIMER13_PWM5'b11110 - TIMER14_pWM5'b11111 - Timer15_PWM Reset Source: mod_g_rst_n
0x44F0 MAIN_CTRL_MMRCFG0_ADC0_CAL — Controls ADC0 calibration sequence (not used)
  [15] ADC0_CAL_CAL_EN — Enable single-ended calibrationSet to 1 to begin single-ended calibration Reset Source: mod_g_rst_n
  [14] ADC0_CAL_DIFF_CAL_EN — Enable differential calibrationSet to 1 to begin differential calibration Reset Source: mod_g_rst_n
  [4:0] ADC0_CAL_CAL_CAP_SEL — Select capacitor for calibrationBits correspond to C5:C1 Reset Source: mod_g_rst_n
0x4700 MAIN_CTRL_MMRCFG0_FSS0_CTRL0 — Controls Flash boot region size for Flash Subsystem0
  [19:0] FSS0_CTRL0_S0_BOOT_SEG — Selects the flash boot segment sizeField values (others are reserved):20'h00001 - 4 kB20'h00002 - 8 kB20'h00004 - 16 kB20'h00008 - 32 kB20'h00010 - 64 kB20'h00020 - 128 kB20'h00040 - 256 kB20'h00080 - 512 kB20'h00100 - 1 MB20'h00200 - 2 MB20'h00400 - 4 MB20'h00800 - 8 MB20'h01000 - 16 MB20'h02000 - 32 MB20'h04000 - 64 MB20'h08000 - 128 MB20'h10000 - 256 MB20'h20000 - 512 MB20'h40000 - 1 GB20'h80000 - 2 GB Reset Source: mod_g_rst_n
0x4704 MAIN_CTRL_MMRCFG0_FSS0_CTRL1 — Controls Flash boot region placement for Flash Subsystem0
  [19:0] FSS0_CTRL1_S0_BOOT_MASK — Determines which (upper 20) address bits to replace with boot_seg signals when accessing the Boot Region (Region 1) Reset Source: mod_g_rst_n
0x4710 MAIN_CTRL_MMRCFG0_FSS1_CTRL0 — Controls Flash boot region size and placement for Flash Subsystem1
  [8] FSS1_CTRL0_S0_BOOT_SIZE — Selects the size of the boot block to be used for the S0 (OSPI1) flash interface Reset Source: mod_g_rst_n
  [5:0] FSS1_CTRL0_S0_BOOT_SEG — Selects the boot block to be used for the S0 (OSPI1) flash interface. If the s0_boot_size is 128 MB then only bits [4:0] of this field are used. Care must be taken to account for the address translation as to not fall off or wrap the address of the flash. (e.g. if both ECC and authentication are enabled for 64 MB boot, the highest valid block number is is 49, as sector 50 is only .2M Bytes in size.) Reset Source: mod_g_rst_n
0x4750 MAIN_CTRL_MMRCFG0_DCC_STAT ro — Interrupt Status of Individual DCC Modules
  [17] DCC_STAT_MCU_DCC1_INTR_DONE — MCU_DCC1 Done Interrupt StatusField values (others are reserved):1'b0 - CLR1'b1 - PEND Reset Source: mod_g_rst_n
  [16] DCC_STAT_MCU_DCC0_INTR_DONE — MCU_DCC0 Done Interrupt StatusField values (others are reserved):1'b0 - CLR1'b1 - PEND Reset Source: mod_g_rst_n
  [n] DCC_STAT_DCC{n}_INTR_DONE (n=0..8) — DCC{n} Done Interrupt StatusField values (others are reserved):1'b0 - CLR1'b1 - PEND Reset Source: mod_g_rst_n
0x4760 MAIN_CTRL_MMRCFG0_R5SS0_CORE0_RL2_CTRL — Controls operation of the RL2 Cache Controller for Main R5 Cluster0 Core0
  [9:8] R5SS0_CORE0_RL2_CTRL_RTXIP_SEL — Selects R5SS0 Core 0 OSPI0 XIP realtime access modeWhen realtime accesses are enabled, read transactions take priority over write transactions. This prevents XIP delays when Flash RWW updates are active.Field values (others are reserved):2'b00 - No realtime accesses2'b01 - Realtime access on RL2 Flash read pending2'b10 - All read accesses are realtime Reset Source: mod_g_rst_n
0x4764 MAIN_CTRL_MMRCFG0_R5SS0_CORE1_RL2_CTRL — Controls operation of the RL2 Cache Controller for Main R5 Cluster0 Core1. Note this register has no effect if Main R5 Cluster0 is operating in lockstep mode.
  [9:8] R5SS0_CORE1_RL2_CTRL_RTXIP_SEL — Selects R5SS0 Core 1 OSPI0 XIP realtime access modeWhen realtime accesses are enabled, read transactions take priority over write transactions. This prevents XIP delays when Flash RWW updates are active.Field values (others are reserved):2'b00 - No realtime accesses2'b01 - Realtime access on RL2 Flash read pending2'b10 - All read accesses are realtime Reset Source: mod_g_rst_n
0x4770 MAIN_CTRL_MMRCFG0_R5SS1_CORE0_RL2_CTRL — Controls operation of the RL2 Cache Controller for Main R5 Cluster1 Core0
  [9:8] R5SS1_CORE0_RL2_CTRL_RTXIP_SEL — Selects R5SS1 Core 0 OSPI0 XIP realtime access modeWhen realtime accesses are enabled, read transactions take priority over write transactions. This prevents XIP delays when Flash RWW updates are active.Field values (others are reserved):2'b00 - No realtime accesses2'b01 - Realtime access on RL2 Flash read pending2'b10 - All read accesses are realtime Reset Source: mod_g_rst_n
